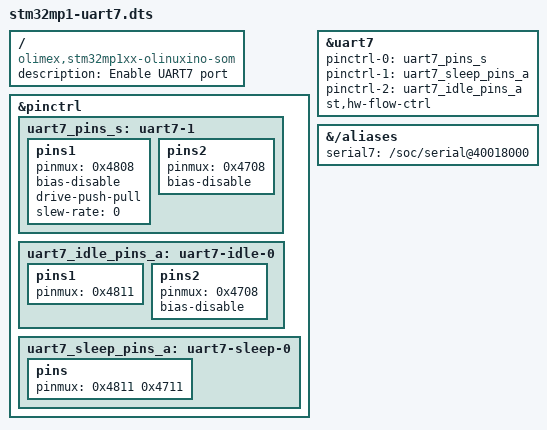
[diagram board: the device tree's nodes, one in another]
/dts-v1/;
/plugin/;
/ {
	compatible = "olimex,stm32mp1xx-olinuxino-som",
		     "olimex,stm32mp1xx-olinuxino-lime";
	description = "Enable UART7 port";

	fragment@0 {
		target = <&pinctrl>;
		__overlay__ {
			uart7_pins_s: uart7-1 {
				pins1 {
					pinmux = <0x4808>;/* uart7_TX */
					bias-disable;
					drive-push-pull;
					slew-rate = <0>;
				};
				pins2 {
					pinmux = <0x4708>; /* uart7_RX */
					bias-disable;
				};
			};
			uart7_idle_pins_a: uart7-idle-0 {
				pins1 {
					pinmux = <0x4811>; /* USART7_TX */
				};
				pins2 {
					pinmux = <0x4708>; /* USART7_RX */
					bias-disable;
				};
			};
			uart7_sleep_pins_a: uart7-sleep-0 {
				pins {
					pinmux = <0x4811 0x4711>;
				};
			};
		};

	};

	fragment@1 {
		target = <&uart7>;
		__overlay__ {
			pinctrl-names = "default";
			pinctrl-0 = <&uart7_pins_s>;
			pinctrl-1 = <&uart7_sleep_pins_a>;
			pinctrl-2 = <&uart7_idle_pins_a>;
			st,hw-flow-ctrl;
			status = "okay";
		};
	};

	fragment@2 {
		target-path = "/aliases";
		__overlay__ {
			serial7 = "/soc/serial@40018000";
		};
	};
};

